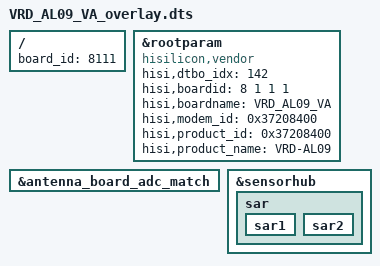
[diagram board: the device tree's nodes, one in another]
/**
 * Copyright (C) 2014 Hisilicon Ltd.
 *
 *  This program is free software; you can redistribute it and/or modify
 *  it under the terms of the GNU General Public License version 2 as
 *  publishhed by the Free Software Foundation.
 */

/dts-v1/;
/plugin/;
/include/ "VRD_Z00_VA_overlay.dtsi"
/include/ "VRD_AL09_VA_pin.dtsi"
/include/ "VRD_AL09_VA_modem_pin.dtsi"

/ {
    board_id = <8111>;
};

	&rootparam {
		compatible = "hisilicon,vendor";
        hisi,dtbo_idx = <142>;
		hisi,boardid = <8 1 1 1>;
		hisi,boardname = "VRD_AL09_VA";
		hisi,modem_id = <0x37208400>;
		hisi,product_id = <0x37208400>;
		hisi,product_name = "VRD-AL09";
	};
	&antenna_board_adc_match{
		status = "ok";
	};
	&sensorhub{
		sar{
			sar1{
				status = "ok";
			};
			sar2{
				status = "ok";
			};
		};
	};
